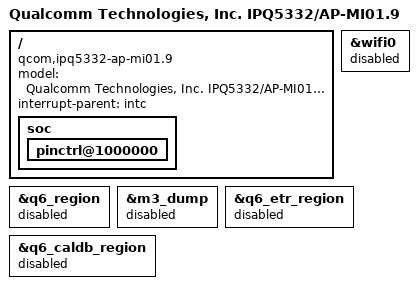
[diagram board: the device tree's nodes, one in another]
// SPDX-License-Identifier: (GPL-2.0+ OR BSD-3-Clause)
/*
 * IPQ5332 AP-MI01.9 board device tree source
 *
 * Copyright (c) 2020-2021 The Linux Foundation. All rights reserved.
 * Copyright (c) 2022-2023 Qualcomm Innovation Center, Inc. All rights reserved.
 */

/dts-v1/;

#include "ipq5332-mi01.2.dts"

/ {
	#address-cells = <0x2>;
	#size-cells = <0x2>;
	model = "Qualcomm Technologies, Inc. IPQ5332/AP-MI01.9";
	compatible = "qcom,ipq5332-ap-mi01.9", "qcom,ipq5332";
	interrupt-parent = <&intc>;

	soc {
		pinctrl@1000000 {
			/delete-node/ leds_pins;
		};

		/delete-node/ leds;
	};
};


&wifi0 {
	status = "disabled";
};

/* Disable IPQ5332 integrated radio's reserved memory */
&q6_region {
	status = "disabled";
};

&m3_dump {
	status = "disabled";
};

&q6_etr_region {
	status = "disabled";
};

&q6_caldb_region {
	status = "disabled";
};
